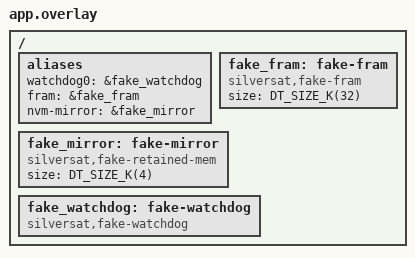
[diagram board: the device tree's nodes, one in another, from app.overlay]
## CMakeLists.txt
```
cmake_minimum_required(VERSION 3.20.0)

# dts/bindings/ holds the fake watchdog's binding; tests/fakes the fake
# FRAM's and mirror's.
set(FAKES ${CMAKE_CURRENT_SOURCE_DIR}/../../fakes)
set(DTS_ROOT ${CMAKE_CURRENT_SOURCE_DIR} ${FAKES})

# watched_app: every flight app health watches is protected, so the tests
# need one that isn't.
set(SS_MESSAGES_EXTRA_APPS ${CMAKE_CURRENT_SOURCE_DIR}/apps)

find_package(Zephyr REQUIRED HINTS $ENV{ZEPHYR_BASE})
project(health_test LANGUAGES C)

# watched_app's attribute row, for the resource map's app_attrs[] (health
# reads it there).
zephyr_compile_definitions(SS_TEST_APP_ATTRS="test_app_attrs.h")
zephyr_include_directories(src)

target_sources(app PRIVATE src/main.c src/fake_watchdog.c ../common/app_test.c
  ${FAKES}/fake_fram.c ${FAKES}/fake_retained_mem.c)
# apps/health, for the status line's own tests (status.h). A test may reach
# into an app; an app may not (DS-12).
target_include_directories(app PRIVATE ../common src ${FAKES} ../../../apps/health)
```

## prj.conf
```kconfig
CONFIG_ZTEST=y

CONFIG_SS_MESSAGES=y
CONFIG_SS_HEALTH=y
# A second flight app's thread, for the stack high-water marks (DS-44).
CONFIG_SS_NVM_APP=y

# Test apps on top of the flight apps need a bigger pool than the
# default; resource_map.h's check fails the build if this is too small.
CONFIG_ZBUS_MSG_SUBSCRIBER_NET_BUF_POOL_SIZE=64

# The fake FRAM and mirror (app.overlay).
CONFIG_EEPROM=y
CONFIG_RETAINED_MEM=y

# Logging, so health's development status line (apps/health/status.c) is
# built and tested.
CONFIG_LOG=y
```

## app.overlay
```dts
/*
 * The watchdog is a fake (src/fake_watchdog.c) that counts feeds and never
 * resets, so the tests can see when health stops feeding it. FRAM and its
 * mirror are fakes too (tests/fakes/), for the checkpoint and boot log.
 */

/ {
	aliases {
		watchdog0 = &fake_watchdog;
		fram = &fake_fram;
		nvm-mirror = &fake_mirror;
	};

	fake_fram: fake-fram {
		compatible = "silversat,fake-fram";
		status = "okay";
		size = <DT_SIZE_K(32)>;
	};

	fake_mirror: fake-mirror {
		compatible = "silversat,fake-retained-mem";
		status = "okay";
		size = <DT_SIZE_K(4)>;
	};

	fake_watchdog: fake-watchdog {
		compatible = "silversat,fake-watchdog";
		status = "okay";
	};
};
```

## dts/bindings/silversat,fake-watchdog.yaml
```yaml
# Copyright (c) 2026 SilverSat
# SPDX-License-Identifier: Apache-2.0

description: |
  A test-only watchdog that counts feeds and never resets (tests/app/health).

compatible: "silversat,fake-watchdog"

include: base.yaml
```

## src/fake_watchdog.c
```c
/*
 * A test-only watchdog driver (silversat,fake-watchdog): it records what
 * health asks of it and counts feeds, and never resets. native_sim has no
 * watchdog that a test could survive.
 *
 * SPDX-License-Identifier: Apache-2.0
 */

#define DT_DRV_COMPAT silversat_fake_watchdog

#include <errno.h>

#include <zephyr/device.h>
#include <zephyr/drivers/watchdog.h>
#include <zephyr/kernel.h>

#include "fake_watchdog.h"

struct fake_watchdog_data {
	struct k_spinlock lock;
	struct fake_watchdog_state state;
	bool installed;
};

static int fake_setup(const struct device *dev, uint8_t options)
{
	struct fake_watchdog_data *data = dev->data;
	k_spinlock_key_t key = k_spin_lock(&data->lock);

	data->state.options = options;
	data->state.started = data->installed;
	k_spin_unlock(&data->lock, key);
	return data->installed ? 0 : -EINVAL;
}

static int fake_disable(const struct device *dev)
{
	ARG_UNUSED(dev);
	return -EPERM; /* like the STM32 IWDG: once started, it can't be stopped */
}

static int fake_install_timeout(const struct device *dev, const struct wdt_timeout_cfg *cfg)
{
	struct fake_watchdog_data *data = dev->data;
	k_spinlock_key_t key = k_spin_lock(&data->lock);

	data->state.timeout_ms = cfg->window.max;
	data->state.flags = cfg->flags;
	data->installed = true;
	k_spin_unlock(&data->lock, key);
	return 0; /* channel 0 */
}

static int fake_feed(const struct device *dev, int channel_id)
{
	struct fake_watchdog_data *data = dev->data;
	k_spinlock_key_t key;

	if (channel_id != 0 || !data->state.started) {
		return -EINVAL;
	}
	key = k_spin_lock(&data->lock);
	data->state.feeds++;
	k_spin_unlock(&data->lock, key);
	return 0;
}

struct fake_watchdog_state fake_watchdog_state(const struct device *dev)
{
	struct fake_watchdog_data *data = dev->data;
	k_spinlock_key_t key = k_spin_lock(&data->lock);
	struct fake_watchdog_state state = data->state;

	k_spin_unlock(&data->lock, key);
	return state;
}

static DEVICE_API(wdt, fake_watchdog_api) = {
	.setup = fake_setup,
	.disable = fake_disable,
	.install_timeout = fake_install_timeout,
	.feed = fake_feed,
};

static struct fake_watchdog_data fake_watchdog_data_0;

DEVICE_DT_INST_DEFINE(0, NULL, NULL, &fake_watchdog_data_0, NULL, POST_KERNEL,
		      CONFIG_KERNEL_INIT_PRIORITY_DEVICE, &fake_watchdog_api);
```

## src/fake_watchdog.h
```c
/*
 * A test-only watchdog: counts feeds, never resets. See fake_watchdog.c.
 *
 * SPDX-License-Identifier: Apache-2.0
 */

#ifndef SILVERSAT_TESTS_FAKE_WATCHDOG_H_
#define SILVERSAT_TESTS_FAKE_WATCHDOG_H_

#include <stdint.h>

#include <zephyr/device.h>

struct fake_watchdog_state {
	uint32_t timeout_ms; /* from wdt_install_timeout() */
	uint32_t flags;      /* from wdt_install_timeout() */
	uint8_t options;     /* from wdt_setup() */
	bool started;        /* wdt_setup() was called */
	uint32_t feeds;
};

/* What the fake has been asked to do so far. */
struct fake_watchdog_state fake_watchdog_state(const struct device *dev);

#endif /* SILVERSAT_TESTS_FAKE_WATCHDOG_H_ */
```

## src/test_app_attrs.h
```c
/*
 * Attribute rows for this test's own apps, added to app_attrs[] by the
 * resource map (SS_TEST_APP_ATTRS, set in CMakeLists.txt).
 *
 * SPDX-License-Identifier: Apache-2.0
 */

/* Watched, not protected: health stops it at its threshold (DS-43). */
[APP_ID_WATCHED_APP] = {
	.protected = false,
	.stall_threshold = 3,
	.reenable = REENABLE_GROUND,
	.auto_retry_cap = 0,
	.critical = false,
},

/* Watched, not protected, and critical: stopping it also asks for safe mode (DS-41). */
[APP_ID_CRITICAL_APP] = {
	.protected = false,
	.stall_threshold = 3,
	.reenable = REENABLE_GROUND,
	.auto_retry_cap = 0,
	.critical = true,
},

/* Watched, restarted by health after its cooldown, at most twice (DS-43). */
[APP_ID_AUTO_APP] = {
	.protected = false,
	.stall_threshold = 3,
	.reenable = REENABLE_AUTO,
	.auto_retry_cap = 2,
	.critical = false,
},
```
